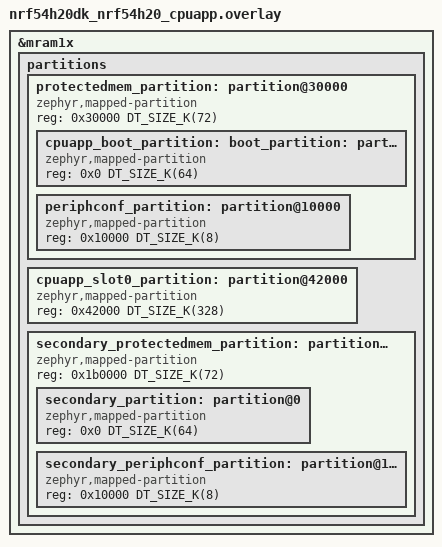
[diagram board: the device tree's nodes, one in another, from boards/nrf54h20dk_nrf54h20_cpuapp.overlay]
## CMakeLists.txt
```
#
# Copyright (c) 2025 Nordic Semiconductor ASA
#
# SPDX-License-Identifier: LicenseRef-Nordic-5-Clause
#

cmake_minimum_required(VERSION 3.20.0)

find_package(Zephyr REQUIRED HINTS $ENV{ZEPHYR_BASE})

project(protectedmem_periphconf)

target_sources(app PRIVATE src/main.c)
```

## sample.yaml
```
sample:
  name: Protected Memory PERIPHCONF Sample
  description: |
    Sample demonstrating UICR.PROTECTEDMEM protection of the periphconf_partition.
    The sample relocates periphconf_partition to be right after
    cpuapp_boot_partition and configures PROTECTEDMEM to protect both partitions.
    The sample writes to the protected area, reboots, and demonstrates that the
    integrity check fails on boot. The secondary firmware then reverts the
    corruption and reboots back into the primary firmware.

common:
  sysbuild: true
  harness: console
  harness_config:
    type: multi_line
    ordered: true
    regex:
      - "Writing test pattern to protected memory\\.\\.\\."
      - "Rebooting after 1s\\."
      - "Secondary: Secondary firmware booted"
      - "Secondary: Booted because of PROTECTEDMEM failure"
      - "Secondary: Rebooting after 1s\\."

tests:
  samples.protectedmem_periphconf.nrf54h20dk:
    tags:
      - sysbuild
      - ci_samples_sdfw
    platform_allow:
      - nrf54h20dk/nrf54h20/cpuapp
    integration_platforms:
      - nrf54h20dk/nrf54h20/cpuapp
    timeout: 7
```

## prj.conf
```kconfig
#
# Copyright (c) 2025 Nordic Semiconductor ASA
#
# SPDX-License-Identifier: LicenseRef-Nordic-5-Clause
#

CONFIG_FLASH=y

# Note: UICR configuration (GEN_UICR_PROTECTEDMEM, etc.) is done in sysbuild/uicr.conf
# for the UICR image, not in the main application's prj.conf
```

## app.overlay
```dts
/*
 * Copyright (c) 2025 Nordic Semiconductor ASA
 *
 * SPDX-License-Identifier: LicenseRef-Nordic-5-Clause
 */

#include "sysbuild/nrf54h20dk_nrf54h20_memory_map.dtsi"
```

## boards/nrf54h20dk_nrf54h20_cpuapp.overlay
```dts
/*
 * Copyright (c) 2026 Nordic Semiconductor ASA
 *
 * SPDX-License-Identifier: LicenseRef-Nordic-5-Clause
 */

/* Delete the original partitions before redefining them */
/delete-node/ &cpuapp_boot_partition;
/delete-node/ &cpuapp_slot0_partition;
/delete-node/ &periphconf_partition;
/delete-node/ &secondary_partition;
/delete-node/ &secondary_periphconf_partition;

&mram1x {
	partitions {
		/* UICR.PROTECTEDMEM region covers cpuapp_boot_partition + periphconf_partition */
		protectedmem_partition: partition@30000 {
			compatible = "zephyr,mapped-partition";
			reg = <0x30000 DT_SIZE_K(72)>;
			#address-cells = <1>;
			#size-cells = <1>;
			ranges = <0x0 0x30000 DT_SIZE_K(72)>;

			cpuapp_boot_partition: boot_partition: partition@0 {
				compatible = "zephyr,mapped-partition";
				reg = <0x0 DT_SIZE_K(64)>;
			};

			/* Place UICR.PERIPHCONF partition right after cpuapp_boot_partition */
			periphconf_partition: partition@10000 {
				compatible = "zephyr,mapped-partition";
				reg = <0x10000 DT_SIZE_K(8)>;
			};
		};

		/* Move cpuapp_slot0_partition to start after periphconf_partition */
		/* periphconf_partition ends at 0x42000, so slot0 starts there */
		cpuapp_slot0_partition: partition@42000 {
			compatible = "zephyr,mapped-partition";
			reg = <0x42000 DT_SIZE_K(328)>;
		};

		/* UICR.SECONDARY.PROTECTEDMEM region
		 * covers secondary_partition + secondary_periphconf_partition
		 */
		secondary_protectedmem_partition: partition@1b0000 {
			compatible = "zephyr,mapped-partition";
			reg = <0x1b0000 DT_SIZE_K(72)>;
			#address-cells = <1>;
			#size-cells = <1>;
			ranges = <0x0 0x1b0000 DT_SIZE_K(72)>;

			secondary_partition: partition@0 {
				compatible = "zephyr,mapped-partition";
				reg = <0x0 DT_SIZE_K(64)>;
			};

			secondary_periphconf_partition: partition@10000 {
				compatible = "zephyr,mapped-partition";
				reg = <0x10000 DT_SIZE_K(8)>;
			};
		};
	};
};
```

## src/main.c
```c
/*
 * Copyright (c) 2025 Nordic Semiconductor ASA.
 *
 * SPDX-License-Identifier: LicenseRef-Nordic-5-Clause
 */

#include <zephyr/kernel.h>
#include <zephyr/sys/printk.h>
#include <zephyr/drivers/flash.h>
#include <zephyr/storage/flash_map.h>
#include <zephyr/arch/cpu.h>

#define MRAM_WRITE_BLOCK_SIZE 16
#define TEST_WRITE_OFFSET                                                                          \
	(PARTITION_OFFSET(protectedmem_partition) + PARTITION_SIZE(protectedmem_partition) -       \
	 MRAM_WRITE_BLOCK_SIZE)

static const uint8_t test_pattern[MRAM_WRITE_BLOCK_SIZE] = {
	0xDE, 0xAD, 0xBE, 0xEF, 0xDE, 0xAD, 0xBE, 0xEF,
	0xDE, 0xAD, 0xBE, 0xEF, 0xDE, 0xAD, 0xBE, 0xEF,
};

int main(void)
{
	printk("Writing test pattern to protected memory...\n");

	const struct device *flash_dev = PARTITION_DEVICE(protectedmem_partition);
	int rc = flash_write(flash_dev, TEST_WRITE_OFFSET, test_pattern, sizeof(test_pattern));

	if (rc) {
		printk("flash_write failed: %d\n", rc);
		return rc;
	}

	printk("Rebooting after 1s. Secondary firmware should boot if protection is working.\n");

	k_msleep(1000);
	NVIC_SystemReset();

	CODE_UNREACHABLE;

	return 0;
}
```
